AUTOSAR XML (schema 4.0)
package /Battery_EV_Components
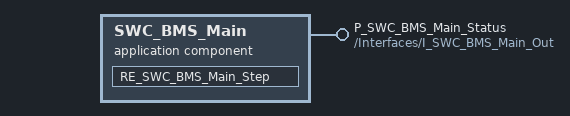
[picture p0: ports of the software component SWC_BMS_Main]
  application sw component type SWC_BMS_Main  # AUTOSAR Application SWC SWC_BMS_Main for Battery EV Safety
    provide port P_SWC_BMS_Main_Status: provided-interface=/Interfaces/I_SWC_BMS_Main_Out
    behavior SWC_BMS_Main_Behavior
      runnable RE_SWC_BMS_Main_Step: symbol=SWC_BMS_Main_Step
  sender receiver interface I_SWC_BMS_Main_Out
    data DE_SWC_BMS_Main_Health: type=/AUTOSAR/Platform/uint32
